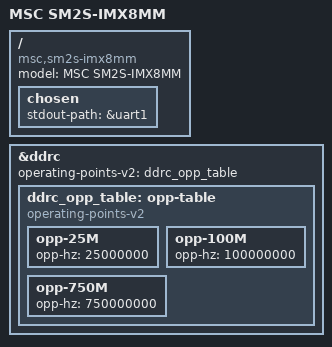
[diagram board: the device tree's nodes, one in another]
// SPDX-License-Identifier: (GPL-2.0+ OR MIT)
/*
 * Copyright 2024 Amarula Solutions B.V.
 * Copyright 2024 Avnet Silica Gmbh
 */

/dts-v1/;

#include <dt-bindings/usb/pd.h>
#include "imx8mm-msc-sm2s.dtsi"

/ {
	model = "MSC SM2S-IMX8MM";
	compatible = "msc,sm2s-imx8mm", "fsl,imx8mm";

	chosen {
		stdout-path = &uart1;
	};
};

&ddrc {
	operating-points-v2 = <&ddrc_opp_table>;

	ddrc_opp_table: opp-table {
		compatible = "operating-points-v2";

		opp-25M {
			opp-hz = /bits/ 64 <25000000>;
		};

		opp-100M {
			opp-hz = /bits/ 64 <100000000>;
		};

		opp-750M {
			opp-hz = /bits/ 64 <750000000>;
		};
	};
};

